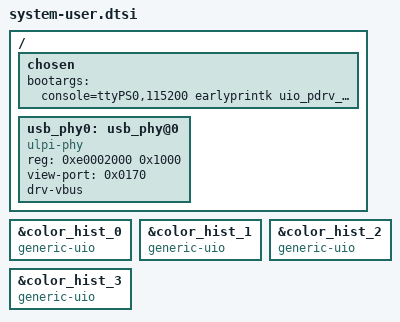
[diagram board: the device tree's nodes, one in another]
/include/ "system-conf.dtsi"
/ {
	chosen {
			bootargs = "console=ttyPS0,115200 earlyprintk uio_pdrv_genirq.of_id=generic-uio root=/dev/mmcblk0p2 rw rootwait";
	};

	usb_phy0: usb_phy@0 {
		compatible = "ulpi-phy";
		#phy-cells = <0>;
		reg = <0xe0002000 0x1000>;
		view-port = <0x0170>;
		drv-vbus;
	};
};


&color_hist_0 {
	compatible = "generic-uio";
};

&color_hist_1 {
	compatible = "generic-uio";
};

&color_hist_2 {
	compatible = "generic-uio";
};

&color_hist_3 {
	compatible = "generic-uio";
};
